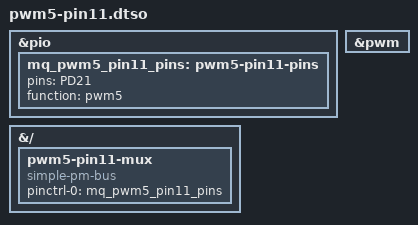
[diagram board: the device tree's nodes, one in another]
// SPDX-License-Identifier: (GPL-2.0+ OR MIT)
// Mangue OS header overlay pwm5-pin11 — GENERATED by tools/gen_overlays.py,
// edit overlays/header_table.py instead.
//
// pin port  role
//  11 PD21  pwm5
// device: /sys/class/pwm/pwmchip0 channel 5

/dts-v1/;
/plugin/;

#include <dt-bindings/gpio/gpio.h>
#include <dt-bindings/interrupt-controller/irq.h>
#include <dt-bindings/input/linux-event-codes.h>

&pio {
	mq_pwm5_pin11_pins: pwm5-pin11-pins {
		pins = "PD21";
		function = "pwm5";
	};
};

&pwm {
	status = "okay";
};

&{/} {
	pwm5-pin11-mux {
		compatible = "simple-pm-bus";
		pinctrl-names = "default";
		pinctrl-0 = <&mq_pwm5_pin11_pins>;
	};
};
